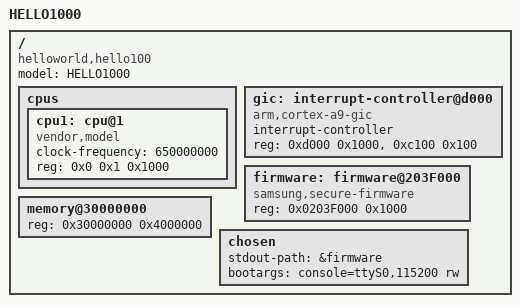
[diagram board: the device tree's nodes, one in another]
/dts-v1/;

/ {
	model = "HELLO1000";
	/* compatible = [<manufacturer>,]<model> */
	compatible = "helloworld,hello100";
	#address-cells = <1>;
	#size-cells = <1>;

	cpus {
		#address-cells = <2>;
		#size-cells = <1>;
		cpu1: cpu@1 {
			compatible = "vendor,model";
			clock-frequency = <650000000>;
			device_type = "cpu";
			reg = <0x0 0x1 0x1000>;
		};
	};

	gic: interrupt-controller@d000 {
		compatible = "arm,cortex-a9-gic";
		#interrupt-cells = <3>;
		#size-cells = <0>;
		interrupt-controller;
		reg = <0xd000 0x1000>, <0xc100 0x100>;
	};

	/* <label>:<name>[@<unit_address> */
	firmware: firmware@203F000 {
		compatible = "samsung,secure-firmware";
		reg = <0x0203F000 0x1000>;
	};

	/* <name>[@<unit_address> */
	memory@30000000 {
		device_type = "memory";
		reg =  <0x30000000 0x4000000>;
	};

	chosen {
		stdout-path = &firmware;
		bootargs = "console=ttyS0,115200 rw";
	};
};

&firmware {
	pinctrl-names = "default";
	status = "okay";
};
